AUTOSAR XML (schema 00050)
package /mercedes_benz/com
  4 x std cpp implementation data type, all with type-emitter=TYPE_EMITTER_ARA:
    MethodRequestStruct: category=STRUCTURE
      cpp implementation data type element message: type-reference=string
    MethodResponseStruct: category=STRUCTURE
      cpp implementation data type element message: type-reference=string
    MsgRequest: type-reference=MethodRequestStruct
    MsgResponse: type-reference=MethodResponseStruct
  service interface AraCM_Method_Benchmark
    namespaces:
      symbol props com_1: symbol=com
      symbol props mercedes_benz_2: symbol=mercedes_benz
      symbol props method_benchmark_3: symbol=method_benchmark
    methods:
      operation MethodIO
        arg m_value_in: type=MsgRequest, direction=IN
        arg m_value_out: type=MsgResponse, direction=OUT
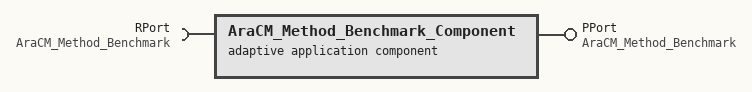
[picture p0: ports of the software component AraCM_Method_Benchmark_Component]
  adaptive application sw component type AraCM_Method_Benchmark_Component
    provide port PPort: provided-interface=AraCM_Method_Benchmark
    require port RPort: required-interface=AraCM_Method_Benchmark
